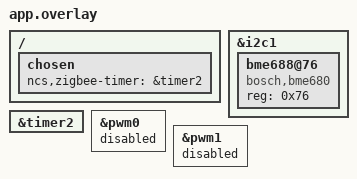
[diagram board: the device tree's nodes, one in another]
/*
 * Copyright (c) 2022 Nordic Semiconductor ASA
 *
 * SPDX-License-Identifier: LicenseRef-Nordic-5-Clause
 */

/ {
	chosen {
		ncs,zigbee-timer = &timer2;
	};
};

&i2c1 {
	status = "okay";

	bme688@76 {
		compatible = "bosch,bme680";
		reg = <0x76>;
		status = "okay";
	};
};

&timer2 {
	status = "okay";
};

/* Disable unused peripherals to reduce power consumption */
&pwm0 {
	status = "disabled";
};
&pwm1 {
	status = "disabled";
};
